# SAMA7G54D4G device description
Architecture: CORTEX-A7; Family: SAMA; Series: SAMA7G
Registers are 32-bit, read-write, reset 0x0 unless marked. A register's access mark holds for its fields unless they carry their own. Offsets are from the block's base; [hi:lo] are bit positions; {n}, {i} and the like mark numbered series; 'fields as' and 'values as' point back to an identical list.

## SECUMOD — Security Module
Instances: SECUMOD 0xE0004000
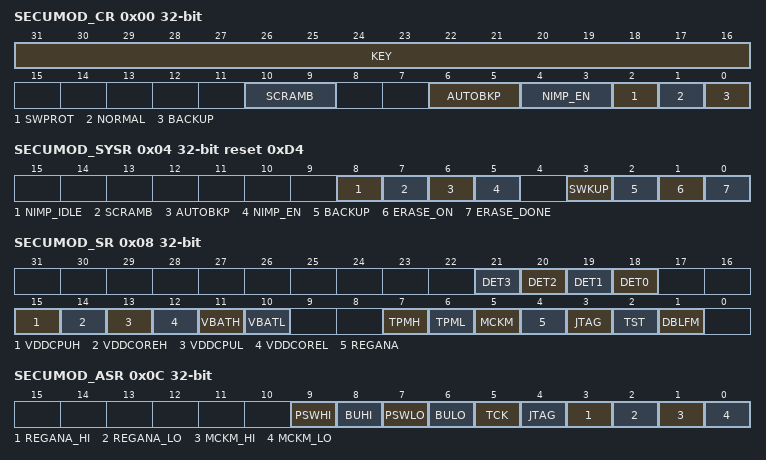
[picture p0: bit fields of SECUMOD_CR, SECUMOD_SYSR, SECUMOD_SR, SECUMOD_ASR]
0x00 SECUMOD_CR wo reset not defined — Control Register
  [31:16] KEY — Password
  [10:9] SCRAMB — Memory Scrambling Enable
    1=Memories are scrambled (default); 2=Memories are not scrambled
  [6:5] AUTOBKP — Automatic Normal to Backup Mode Switching
    1=When in Normal mode, the powerdown of the core supply automatically switches to Backup mode simultaneously with core to backup isolation barrier activation (default); 2=When in Normal mode, the software must switch to Backup mode before powering down the core
  [4:3] NIMP_EN — Non-Imprinting Enable
    0=No effect; 1=The non-imprinting mechanism is authorized to start when core power is off or ahb reset is asserted; 2=The non-imprinting mechanism is disabled (default); 3=The non-imprinting mechanism is authorized to start when core power is off or ahb reset is asserted or cpu is in idle
  [2] SWPROT — Software Protection
    0=No effect; 1=Starts the BUSRAM4KB and BUREG256b Clear content
  [1] NORMAL — Normal Mode
    0=No effect; 1=Switches to Normal mode
  [0] BACKUP — Backup Mode
    0=No effect; 1=Switches to Backup mode
0x04 SECUMOD_SYSR reset 0xD4 — System Status Register
  [8] NIMP_IDLE — "CPU in idle" preliminary condition for non-imprinting (RO)
    0=Idle is not part of preliminary conditions list; 1=Idle is part of preliminary conditions list
  [7] SCRAMB — Scrambling Enabled (RO)
    0=Disabled; 1=Enabled
  [6] AUTOBKP — Automatic Backup Mode Enabled (RO)
    0=Disabled; 1=Enabled
  [5] NIMP_EN — Non-Imprinting Enabled (RO)
    0=Disabled; 1=Enabled
  [3] SWKUP — SWKUP State (RO)
    0=No SWKUP signal sent since the last clear; 1=SWKUP signal has been sent since the last clear
  [2] BACKUP — Backup Mode (RO)
    0=Normal mode active; 1=Backup mode active
  [1] ERASE_ON — Erase Process Ongoing (RO)
    0=Erase automaton is not running; 1=Erase automaton is currently running, memories are not accessible
  [0] ERASE_DONE — Erasable Memories State (RW)
    0=Secure memories content has not been erased since the last clear; 1=Secure memories content has been erased since the last clear. The user must write '1' into this bit to clear this flag. Note that not clearing this flag does not prevent the next erase processes. This flag also activates the SECURAM interrupt line as long as it is not cleared.
0x08 SECUMOD_SR ro — Status Register
  [n+18] DET{n} (n=0..3) — PIOBU Intrusion Detector
  [15] VDDCPUH — High VDDCPU Voltage Monitor
  [14] VDDCOREH — High VDDCORE Voltage Monitor
  [13] VDDCPUL — Low VDDCPU Voltage Monitor
  [12] VDDCOREL — Low VDDCORE Voltage Monitor
  [11] VBATH — High VBAT Voltage Monitor
  [10] VBATL — Low VBAT Voltage Monitor
  [7] TPMH — High Temperature Monitor
  [6] TPML — Low Temperature Monitor
  [5] MCKM — Master Clock Monitor
  [4] REGANA — VDDANA regulator Monitor
  [3] JTAG — JTAG Pins Monitor
  [2] TST — Test Pin Monitor
  [1] DBLFM — Double Frequency Monitor
0x0C SECUMOD_ASR ro — Auxiliary Status Register
  [9] PSWHI — VDDIN33 (used as secondary LDO power source through backup powerswitch) low alarm detected is the cause of VBATL flag in SECUMOD_SR.
  [8] BUHI — VBAT high alarm detected is the cause of VBATH flag in SECUMOD_SR.
  [7] PSWLO — VDDIN33 (used as secondary LDO power source through backup powerswitch) low alarm detected is the cause of VBATL flag in SECUMOD_SR.
  [6] BULO — VBAT low alarm detected is the cause of VBATL flag in SECUMOD_SR.
  [5] TCK — TCK/TMS activity detected is the cause of JTAG flag in SECUMOD_SR.
  [4] JTAG — JTAGSEL or processor debug acknowledge is the cause of JTAG flag in SECUMOD_SR.
  [3] REGANA_HI — High voltage alarm from VDDANA regulator is the cause of REGANA flag in SECUMOD_SR.
  [2] REGANA_LO — Low voltage alarm from VDDANA regulator is the cause of REGANA flag in SECUMOD_SR.
  [1] MCKM_HI — High frequency limit reached is the cause of MCKM flag in SECUMOD_SR.
  [0] MCKM_LO — Low frequency limit reached is the cause of MCKM flag in SECUMOD_SR.
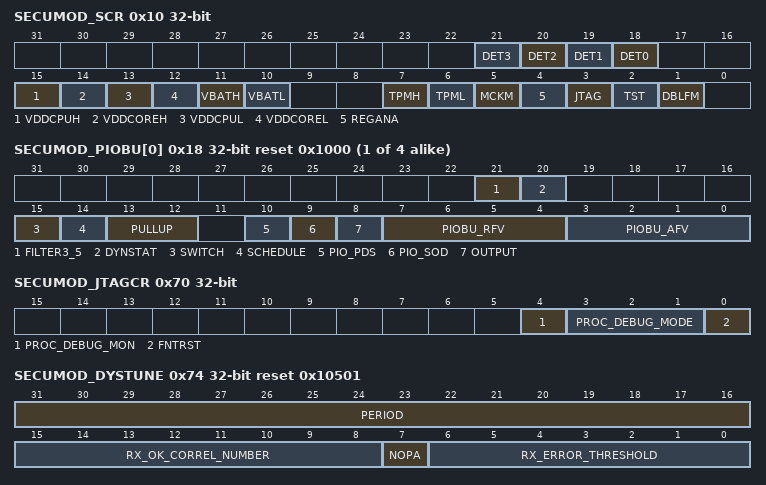
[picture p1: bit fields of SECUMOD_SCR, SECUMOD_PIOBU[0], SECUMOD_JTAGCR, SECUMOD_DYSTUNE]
0x10 SECUMOD_SCR wo reset not defined (atomic clear of SECUMOD_SR) — Status Clear Register
  fields as SECUMOD_SR
0x14 SECUMOD_RAMRDY ro reset not defined — RAM Access Ready Register
  [0] READY — Ready for system access flag
{0x18+4i} SECUMOD_PIOBU[{i}] (i=0..3) reset 0x1000 — PIO Backup Register x
  [21] FILTER3_5 — Filter for Dynamic Signatures Input
    0=3-stage majority vote (default); 1=5-stage majority vote
  [20] DYNSTAT — Switch for Static or Dynamic Detection Intrusion
    0=Static detection intrusion (default) mode is selected; 1=Dynamic detection intrusion mode is selected
  [15] SWITCH — Switch State for Intrusion Detection
    0=Input default state is low level; 1=Input default state is high level
  [14] SCHEDULE — Pullup/Pulldown Scheduled
    0=Pullup/Pulldown is not scheduled; 1=Pullup/Pulldown is scheduled
  [13:12] PULLUP — Programmable Pullup State
  [10] PIO_PDS — Level on the Pin in Input Mode (OUTPUT = 0) (Read-only)
    0=The I/O line is at level 0; 1=The I/O line is at level 1
  [9] PIO_SOD — Set/Clear the I/O Line when configured in Output Mode (OUTPUT =1)
    0=Clears the data to be driven on the I/O line; 1=Sets the data to be driven on the I/O line
  [8] OUTPUT — Configure I/O Line in Input/Output
    0=The I/O line is a pure input; 1=The I/O line is enabled in output
  [7:4] PIOBU_RFV — PIOBUx Reset Filter Value
  [3:0] PIOBU_AFV — PIOBU Alarm Filter Value
0x58 SECUMOD_VBUFR reset 0x7 — VBAT Filter Register
  [2:0] VBATFV — VBAT Filter Value
0x64 SECUMOD_VCOREFR reset 0x1FFF — VDDCORE Filter Register
  [12:0] VDDCORE_DBTV — VDDCORE Programmable Debouncing Time Value
0x68 SECUMOD_VCPUFR reset 0x1FFF — VDDCPU Filter Register
  [12:0] VDDCPU_DBTV — VDDCPU Programmable Debouncing Time Value
0x70 SECUMOD_JTAGCR — JTAG Protection Control Register
  [4] PROC_DEBUG_MON — Debug Acknowledge (DBGACK) Monitoring
    0=The processor's pin DBGACK is not monitored; as a consequence, the software can access debug features of the processor without causing an intrusion in the Security Module; 1=The processor's pin DBGACK is monitored. Processor entering Debug mode triggers an intrusion.
  [3:1] PROC_DEBUG_MODE — Invasive/Non-Invasive Secure/Non-Secure Debug Permissions
  [0] FNTRST — Force NTRST
    0=The processor's TAP controller access and Boundary JTAG are not blocked by the Security Module; 1=NDBGRESET of the processor's TAP controller and Boundary JTAG reset are held low, preventing the processor to switch to debug state and Boundary JTAG to work
0x74 SECUMOD_DYSTUNE reset 0x10501 — Dynamic Signatures Tuning Register
  [31:16] PERIOD — Signature Clock Period
  [15:8] RX_OK_CORREL_NUMBER — Error Counter Reset Threshold
  [7] NOPA — No Periodic Alarm
    0=The alarm is regenerated periodically while intrusion is maintained; 1=The alarm is not regenerated periodically while intrusion is maintained
  [6:0] RX_ERROR_THRESHOLD — Error Detection Threshold
0x78 SECUMOD_SCRKEY reset not defined — Scrambling Key Register
  [31:0] SCRKEY — Scrambling Key Value
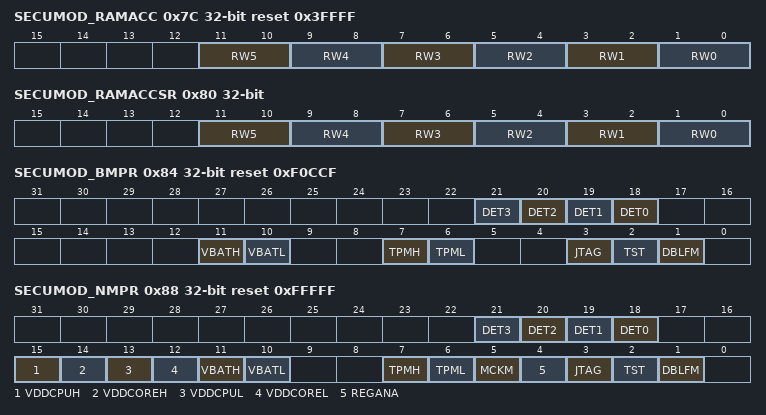
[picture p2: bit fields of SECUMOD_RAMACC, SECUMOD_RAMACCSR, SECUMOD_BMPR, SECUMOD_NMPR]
0x7C SECUMOD_RAMACC reset 0x3FFFF — RAM Access Rights Register
  [11:10] RW5 — Access right for RAM region [5 Kbytes; 6 Kbytes] (register bank BUREG256b)
  [9:8] RW4 — Access right for RAM region [4 Kbytes; 5 Kbytes]
  [7:6] RW3 — Access right for RAM region [3 Kbytes; 4 Kbytes]
  [5:4] RW2 — Access right for RAM region [2 Kbytes; 3 Kbytes]
  [3:2] RW1 — Access right for RAM region [1 Kbyte; 2 Kbytes]
  [1:0] RW0 — Access right for RAM region [0; 1 Kbyte]
0x80 SECUMOD_RAMACCSR — RAM Access Rights Status Register
  [11:10] RW5 — Access right status for RAM region [5 Kbytes; 6 Kbytes] (register bank BUREG256b)
  [9:8] RW4 — Access right status for RAM region [4 Kbytes; 5 Kbytes]
  [7:6] RW3 — Access right status for RAM region [3 Kbytes; 4 Kbytes]
  [5:4] RW2 — Access right status for RAM region [2 Kbytes; 3 Kbytes]
  [3:2] RW1 — Access right status for RAM region [1 Kbytes; 2 Kbytes]
  [1:0] RW0 — Access right status for RAM region [0; 1 Kbyte]
0x84 SECUMOD_BMPR reset 0xF0CCF — Backup Mode Protection Register
  [n+18] DET{n} (n=0..3) — PIOBU Intrusion Detector Protection
  [11] VBATH — High VBAT Voltage Monitor Protection
  [10] VBATL — Low VBAT Voltage Monitor Protection
  [7] TPMH — High Temperature Monitor Protection
  [6] TPML — Low Temperature Monitor Protection
  [3] JTAG — JTAG Pin Protection
  [2] TST — Test Pin Protection
  [1] DBLFM — Double Frequency Monitor Protection
0x88 SECUMOD_NMPR reset 0xFFFFF — Normal Mode Protection Register
  [n+18] DET{n} (n=0..3) — PIOBU Intrusion Detector Protection
  [15] VDDCPUH — High VDDCPU Voltage Monitor Protection
  [14] VDDCOREH — High VDDCORE Voltage Monitor Protection
  [13] VDDCPUL — Low VDDCPU Voltage Monitor Protection
  [12] VDDCOREL — Low VDDCORE Voltage Monitor Protection
  [11] VBATH — High VBAT Voltage Monitor Protection
  [10] VBATL — Low VBAT Voltage Monitor Protection
  [7] TPMH — High Temperature Monitor Protection
  [6] TPML — Low Temperature Monitor Protection
  [5] MCKM — Master Clock Monitor Protection
  [4] REGANA — VDDANA regulator voltage monitor Protection
  [3] JTAG — JTAG Pin Protection
  [2] TST — Test Pin Protection
  [1] DBLFM — Double Frequency Monitor Protection
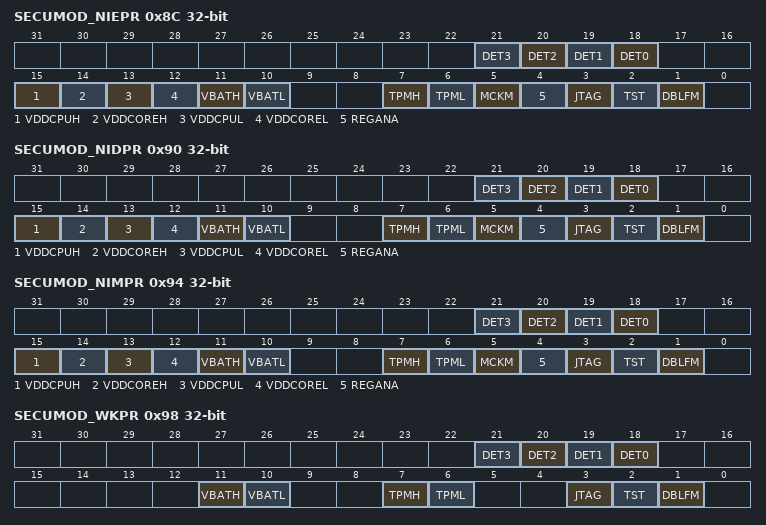
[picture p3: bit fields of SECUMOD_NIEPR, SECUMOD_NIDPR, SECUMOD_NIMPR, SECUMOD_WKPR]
0x8C SECUMOD_NIEPR wo reset not defined — Normal Interrupt Enable Protection Register
  [n+18] DET{n} (n=0..3) — PIOBU Intrusion Detector Protection Interrupt Enable
  [15] VDDCPUH — High VDDCPU Voltage Monitor Protection Interrupt Enable
  [14] VDDCOREH — High VDDCORE Voltage Monitor Protection Interrupt Enable
  [13] VDDCPUL — Low VDDCPU Voltage Monitor Protection Interrupt Enable
  [12] VDDCOREL — Low VDDCORE Voltage Monitor Protection Interrupt Enable
  [11] VBATH — High VBAT Voltage Monitor Protection Interrupt Enable
  [10] VBATL — Low VBAT Voltage Monitor Protection Interrupt Enable
  [7] TPMH — High Temperature Monitor Protection Interrupt Enable
  [6] TPML — Low Temperature Monitor Protection Interrupt Enable
  [5] MCKM — Master Clock Monitor Protection Interrupt Enable
  [4] REGANA — VDDANA regulator voltage monitor Protection Interrupt Enable
  [3] JTAG — JTAG Pin Protection Interrupt Enable
  [2] TST — Test Pin Protection Interrupt Enable
  [1] DBLFM — Double Frequency Monitor Protection Interrupt Enable
0x90 SECUMOD_NIDPR wo reset not defined — Normal Interrupt Disable Protection Register
  [n+18] DET{n} (n=0..3) — PIOBU Intrusion Detector Protection Interrupt Disable
  [15] VDDCPUH — High VDDCPU Voltage Monitor Protection Interrupt Disable
  [14] VDDCOREH — High VDDCORE Voltage Monitor Protection Interrupt Disable
  [13] VDDCPUL — Low VDDCPU Voltage Monitor Protection Interrupt Disable
  [12] VDDCOREL — Low VDDCORE Voltage Monitor Protection Interrupt Disable
  [11] VBATH — High VBAT Voltage Monitor Protection Interrupt Disable
  [10] VBATL — Low VBAT Voltage Monitor Protection Interrupt Disable
  [7] TPMH — High Temperature Monitor Protection Interrupt Disable
  [6] TPML — Low Temperature Monitor Protection Interrupt Disable
  [5] MCKM — Master Clock Monitor Protection Interrupt Disable
  [4] REGANA — VDDANA regulator voltage monitor Protection Interrupt Disable
  [3] JTAG — JTAG Pin Protection Interrupt Disable
  [2] TST — Test Pin Protection Interrupt Disable
  [1] DBLFM — Double Frequency Monitor Protection Interrupt Disable
0x94 SECUMOD_NIMPR ro — Normal Interrupt Mask Protection Register
  [n+18] DET{n} (n=0..3) — PIOBU Intrusion Detector Protection Interrupt Mask
  [15] VDDCPUH — High VDDCPU Voltage Monitor Protection Interrupt Mask
  [14] VDDCOREH — High VDDCORE Voltage Monitor Protection Interrupt Mask
  [13] VDDCPUL — Low VDDCPU Voltage Monitor Protection Interrupt Mask
  [12] VDDCOREL — Low VDDCORE Voltage Monitor Protection Interrupt Mask
  [11] VBATH — High VBAT Voltage Monitor Protection Interrupt Mask
  [10] VBATL — Low VBAT Voltage Monitor Protection Interrupt Mask
  [7] TPMH — High Temperature Monitor Protection Interrupt Mask
  [6] TPML — Low Temperature Monitor Protection Interrupt Mask
  [5] MCKM — Master Clock Monitor Protection Interrupt Mask
  [4] REGANA — VDDANA regulator voltage monitor Protection Interrupt Mask
  [3] JTAG — JTAG Pin Protection Interrupt Mask
  [2] TST — Test Pin Protection Interrupt Mask
  [1] DBLFM — Double Frequency Monitor Protection Interrupt Mask
0x98 SECUMOD_WKPR — Wakeup Protection Register
  fields as SECUMOD_BMPR
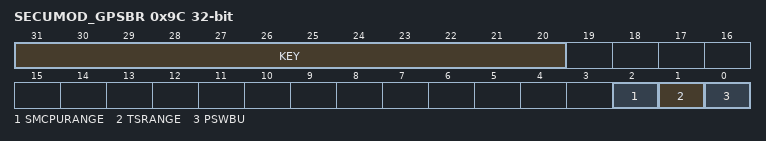
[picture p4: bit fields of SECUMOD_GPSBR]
0x9C SECUMOD_GPSBR reset not defined — General Purpose Security Bits Register
  [31:20] KEY — Safety key, must write 0xD5E to enable GPSBR modifications
  [2] SMCPURANGE
    0=Sets SM VDDCPU thresholds for 600MHz max frequency operation; 1=Sets SM VDDCPU thresholds for 800MHz max frequency operation
  [1] TSRANGE
    0=Sets Temperature Sensor high threshold to 105\xfb C; 1=Sets Temperature Sensor high threshold to 120\xfb C
  [0] PSWBU — Enables the backup domain power source to automatically switch from VDDIN33 to VBAT supply when security module enters "backup" mode. Refer to SFRBU specification for details on backup power switch control.
